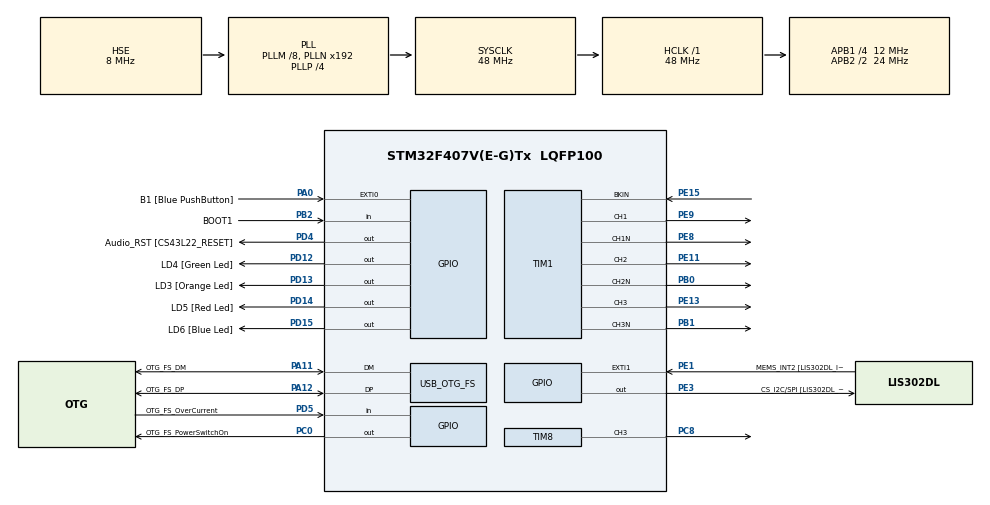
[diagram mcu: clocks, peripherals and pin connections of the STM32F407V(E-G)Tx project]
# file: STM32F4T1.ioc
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FREERTOS.Tasks01=defaultTask,0,128,StartDefaultTask,Default,NULL,Dynamic,NULL,NULL;TNBlinky,-3,128,ThreadBlinky,As external,NULL,Dynamic,NULL,NULL
Mcu.Family=STM32F4
Mcu.Name=STM32F407V(E-G)Tx
Mcu.Package=LQFP100
NVIC.OTG_FS_IRQn=true\:5\:0\:false\:false\:true\:true
NVIC.PriorityGroup=NVIC_PRIORITYGROUP_4
NVIC.TIM6_DAC_IRQn=true\:0\:0\:false\:false\:true\:false
NVIC.TimeBase=TIM6_DAC_IRQn
NVIC.TimeBaseIP=TIM6
PA0-WKUP.GPIO_Label=B1 [Blue PushButton]
PA0-WKUP.Signal=GPXTI0
PA10.GPIO_Label=OTG_FS_ID
PA10.GPIO_Mode=GPIO_MODE_AF_PP
PA10.GPIO_PuPd=GPIO_NOPULL
PA10.GPIO_Speed=GPIO_SPEED_FREQ_LOW
PA10.Signal=USB_OTG_FS_ID
PA11.GPIO_Label=OTG_FS_DM
PA11.GPIO_Mode=GPIO_MODE_AF_PP
PA11.GPIO_PuPd=GPIO_NOPULL
PA11.GPIO_Speed=GPIO_SPEED_FREQ_LOW
PA11.Mode=Device_Only
PA11.Signal=USB_OTG_FS_DM
PA12.GPIO_Label=OTG_FS_DP
PA12.GPIO_Mode=GPIO_MODE_AF_PP
PA12.GPIO_PuPd=GPIO_NOPULL
PA12.GPIO_Speed=GPIO_SPEED_FREQ_LOW
PA12.Mode=Device_Only
PA12.Signal=USB_OTG_FS_DP
PA13.GPIO_Label=SWDIO
PA13.Signal=SYS_JTMS-SWDIO
PA14.GPIO_Label=SWCLK
PA14.Signal=SYS_JTCK-SWCLK
PA4.GPIO_Label=I2S3_WS [CS43L22_LRCK]
PA4.GPIO_Mode=GPIO_MODE_AF_PP
PA4.GPIO_PuPd=GPIO_NOPULL
PA4.GPIO_Speed=GPIO_SPEED_FREQ_LOW
PA4.Signal=I2S3_WS
PA5.GPIO_Label=SPI1_SCK [LIS302DL_SCL/SPC]
PA5.GPIO_Mode=GPIO_MODE_AF_PP
PA5.GPIO_PuPd=GPIO_NOPULL
PA5.GPIO_Speed=GPIO_SPEED_FREQ_LOW
PA5.Signal=SPI1_SCK
PA6.GPIO_Label=SPI1_MISO [LIS302DL_SDO]
PA6.GPIO_Mode=GPIO_MODE_AF_PP
PA6.GPIO_PuPd=GPIO_NOPULL
PA6.GPIO_Speed=GPIO_SPEED_FREQ_LOW
PA6.Signal=SPI1_MISO
PA7.GPIO_Label=SPI1_MOSI [LIS302DL_SDA/SDI/SDO]
PA7.GPIO_Mode=GPIO_MODE_AF_PP
PA7.GPIO_PuPd=GPIO_NOPULL
PA7.GPIO_Speed=GPIO_SPEED_FREQ_LOW
PA7.Signal=SPI1_MOSI
PA9.GPIO_Label=VBUS_FS
PA9.GPIO_Mode=GPIO_MODE_INPUT
PA9.GPIO_PuPd=GPIO_NOPULL
PA9.Signal=USB_OTG_FS_VBUS
PB0.Mode=PWM Generation2 CH2 CH2N
PB0.Signal=TIM1_CH2N
PB1.Mode=PWM Generation3 CH3 CH3N
PB1.Signal=TIM1_CH3N
PB10.GPIO_Label=CLK_IN [MP45DT02_CLK]
PB10.GPIO_Mode=GPIO_MODE_AF_PP
PB10.GPIO_PuPd=GPIO_NOPULL
PB10.GPIO_Speed=GPIO_SPEED_FREQ_LOW
PB10.Signal=I2S2_CK
PB2.GPIO_Label=BOOT1
PB2.GPIO_Mode=GPIO_MODE_INPUT
PB2.GPIO_PuPd=GPIO_NOPULL
PB2.Signal=GPIO_Input
PB3.GPIO_Label=SWO
PB3.Signal=SYS_JTDO-SWO
PB6.GPIO_Label=Audio_SCL [CS43L22_SCL]
PB6.GPIO_Mode=GPIO_MODE_AF_OD
PB6.GPIO_PuPd=GPIO_NOPULL
PB6.GPIO_Speed=GPIO_SPEED_FREQ_LOW
PB6.Signal=I2C1_SCL
PB9.GPIO_Label=Audio_SDA [CS43L22_SDA]
PB9.GPIO_Mode=GPIO_MODE_AF_OD
PB9.GPIO_PuPd=GPIO_NOPULL
PB9.GPIO_Speed=GPIO_SPEED_FREQ_LOW
PB9.Signal=I2C1_SDA
PC0.GPIO_Label=OTG_FS_PowerSwitchOn
PC0.GPIO_PuPd=GPIO_NOPULL
PC0.GPIO_Speed=GPIO_SPEED_FREQ_LOW
PC0.PinState=GPIO_PIN_SET
PC0.Signal=GPIO_Output
PC10.GPIO_Label=I2S3_SCK [CS43L22_SCLK]
PC10.GPIO_Mode=GPIO_MODE_AF_PP
PC10.GPIO_PuPd=GPIO_NOPULL
PC10.GPIO_Speed=GPIO_SPEED_FREQ_LOW
PC10.Signal=I2S3_CK
PC12.GPIO_Label=I2S3_SD [CS43L22_SDIN]
PC12.GPIO_Mode=GPIO_MODE_AF_PP
PC12.GPIO_PuPd=GPIO_NOPULL
PC12.GPIO_Speed=GPIO_SPEED_FREQ_LOW
PC12.Signal=I2S3_SD
PC14-OSC32_IN.GPIO_Label=PC14-OSC32_IN
PC14-OSC32_IN.Mode=LSE-External-Oscillator
PC14-OSC32_IN.Signal=RCC_OSC32_IN
PC15-OSC32_OUT.GPIO_Label=PC15-OSC32_OUT
PC15-OSC32_OUT.Mode=LSE-External-Oscillator
PC15-OSC32_OUT.Signal=RCC_OSC32_OUT
PC3.GPIO_Label=PDM_OUT [MP45DT02_DOUT]
PC3.GPIO_Mode=GPIO_MODE_AF_PP
PC3.GPIO_PuPd=GPIO_NOPULL
PC3.GPIO_Speed=GPIO_SPEED_FREQ_LOW
PC3.Signal=I2S2_SD
PC7.GPIO_Label=I2S3_MCK [CS43L22_MCLK]
PC7.GPIO_Mode=GPIO_MODE_AF_PP
PC7.GPIO_PuPd=GPIO_NOPULL
PC7.GPIO_Speed=GPIO_SPEED_FREQ_LOW
PC7.Signal=I2S3_MCK
PC8.Signal=S_TIM8_CH3
PD12.GPIO_Label=LD4 [Green Led]
PD12.GPIO_PuPd=GPIO_NOPULL
PD12.GPIO_Speed=GPIO_SPEED_FREQ_LOW
PD12.Signal=GPIO_Output
PD13.GPIO_Label=LD3 [Orange Led]
PD13.GPIO_PuPd=GPIO_NOPULL
PD13.GPIO_Speed=GPIO_SPEED_FREQ_LOW
PD13.Signal=GPIO_Output
PD14.GPIO_Label=LD5 [Red Led]
PD14.GPIO_PuPd=GPIO_NOPULL
PD14.GPIO_Speed=GPIO_SPEED_FREQ_LOW
PD14.Signal=GPIO_Output
PD15.GPIO_Label=LD6 [Blue Led]
PD15.GPIO_PuPd=GPIO_NOPULL
PD15.GPIO_Speed=GPIO_SPEED_FREQ_LOW
PD15.Signal=GPIO_Output
PD4.GPIO_Label=Audio_RST [CS43L22_RESET]
PD4.GPIO_PuPd=GPIO_NOPULL
PD4.GPIO_Speed=GPIO_SPEED_FREQ_LOW
PD4.Signal=GPIO_Output
PD5.GPIO_Label=OTG_FS_OverCurrent
PD5.GPIO_Mode=GPIO_MODE_INPUT
PD5.GPIO_PuPd=GPIO_NOPULL
PD5.Signal=GPIO_Input
PE1.GPIO_Label=MEMS_INT2 [LIS302DL_INT2]
PE1.GPIO_ModeDefaultEXTI=GPIO_MODE_EVT_RISING
PE1.GPIO_PuPd=GPIO_NOPULL
PE1.Signal=GPXTI1
PE11.Signal=S_TIM1_CH2
PE13.Signal=S_TIM1_CH3
PE15.Mode=Activate-Break-Input
PE15.Signal=TIM1_BKIN
PE3.GPIO_Label=CS_I2C/SPI [LIS302DL_CS_I2C/SPI]
PE3.GPIO_PuPd=GPIO_NOPULL
PE3.GPIO_Speed=GPIO_SPEED_FREQ_LOW
PE3.Signal=GPIO_Output
PE8.Mode=PWM Generation1 CH1 CH1N
PE8.Signal=TIM1_CH1N
PE9.Signal=S_TIM1_CH1
PH0-OSC_IN.GPIO_Label=PH0-OSC_IN
PH0-OSC_IN.Mode=HSE-External-Oscillator
PH0-OSC_IN.Signal=RCC_OSC_IN
PH1-OSC_OUT.GPIO_Label=PH1-OSC_OUT
PH1-OSC_OUT.Mode=HSE-External-Oscillator
PH1-OSC_OUT.Signal=RCC_OSC_OUT
ProjectManager.HeapSize=0x200
ProjectManager.StackSize=0x400
ProjectManager.TargetToolchain=SW4STM32
RCC.48MHZClocksFreq_Value=48000000
RCC.AHBFreq_Value=48000000
RCC.APB1CLKDivider=RCC_HCLK_DIV4
RCC.APB1Freq_Value=12000000
RCC.APB1TimFreq_Value=24000000
RCC.APB2CLKDivider=RCC_HCLK_DIV2
RCC.APB2Freq_Value=24000000
RCC.APB2TimFreq_Value=48000000
RCC.CortexFreq_Value=48000000
RCC.HCLKFreq_Value=48000000
RCC.HSE_VALUE=8000000
RCC.HSI_VALUE=16000000
RCC.PLLM=8
RCC.PLLP=RCC_PLLP_DIV4
RCC.SYSCLKFreq_VALUE=48000000
RCC.SYSCLKSource=RCC_SYSCLKSOURCE_PLLCLK
RCC.VCOOutputFreq_Value=192000000
SH.S_TIM1_CH1.0=TIM1_CH1,PWM Generation1 CH1 CH1N
SH.S_TIM1_CH2.0=TIM1_CH2,PWM Generation2 CH2 CH2N
SH.S_TIM1_CH3.0=TIM1_CH3,PWM Generation3 CH3 CH3N
SH.S_TIM8_CH3.0=TIM8_CH3,PWM Generation3 CH3
TIM1.Channel-PWM\ Generation1\ CH1\ CH1N=TIM_CHANNEL_1
TIM1.Channel-PWM\ Generation2\ CH2\ CH2N=TIM_CHANNEL_2
TIM1.Channel-PWM\ Generation3\ CH3\ CH3N=TIM_CHANNEL_3
TIM8.Channel-PWM\ Generation3\ CH3=TIM_CHANNEL_3
USB_DEVICE.CLASS_NAME_FS=CDC
USB_DEVICE.VirtualModeFS=Cdc_FS
USB_OTG_FS.VirtualMode=Device_Only
VP_FREERTOS_VS_ENABLE.Mode=Enabled
VP_SYS_VS_tim6.Mode=TIM6
VP_TIM1_VS_ClockSourceINT.Mode=Internal
VP_USB_DEVICE_VS_USB_DEVICE_CDC_FS.Mode=CDC_FS
board=STM32F4DISCOVERY

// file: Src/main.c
/**
  ******************************************************************************
  * File Name          : main.c
  * Description        : Main program body
  ******************************************************************************
  *
  * Copyright (c) 2017 STMicroelectronics International N.V.
  * All rights reserved.
  *
  * Redistribution and use in source and binary forms, with or without
  * modification, are permitted, provided that the following conditions are met:
  *
  * 1. Redistribution of source code must retain the above copyright notice,
  *    this list of conditions and the following disclaimer.
  * 2. Redistributions in binary form must reproduce the above copyright notice,
  *    this list of conditions and the following disclaimer in the documentation
  *    and/or other materials provided with the distribution.
  * 3. Neither the name of STMicroelectronics nor the names of other
  *    contributors to this software may be used to endorse or promote products
  *    derived from this software without specific written permission.
  * 4. This software, including modifications and/or derivative works of this
  *    software, must execute solely and exclusively on microcontroller or
  *    microprocessor devices manufactured by or for STMicroelectronics.
  * 5. Redistribution and use of this software other than as permitted under
  *    this license is void and will automatically terminate your rights under
  *    this license.
  *
  * THIS SOFTWARE IS PROVIDED BY STMICROELECTRONICS AND CONTRIBUTORS "AS IS"
  * AND ANY EXPRESS, IMPLIED OR STATUTORY WARRANTIES, INCLUDING, BUT NOT
  * LIMITED TO, THE IMPLIED WARRANTIES OF MERCHANTABILITY, FITNESS FOR A
  * PARTICULAR PURPOSE AND NON-INFRINGEMENT OF THIRD PARTY INTELLECTUAL PROPERTY
  * RIGHTS ARE DISCLAIMED TO THE FULLEST EXTENT PERMITTED BY LAW. IN NO EVENT
  * SHALL STMICROELECTRONICS OR CONTRIBUTORS BE LIABLE FOR ANY DIRECT, INDIRECT,
  * INCIDENTAL, SPECIAL, EXEMPLARY, OR CONSEQUENTIAL DAMAGES (INCLUDING, BUT NOT
  * LIMITED TO, PROCUREMENT OF SUBSTITUTE GOODS OR SERVICES; LOSS OF USE, DATA,
  * OR PROFITS; OR BUSINESS INTERRUPTION) HOWEVER CAUSED AND ON ANY THEORY OF
  * LIABILITY, WHETHER IN CONTRACT, STRICT LIABILITY, OR TORT (INCLUDING
  * NEGLIGENCE OR OTHERWISE) ARISING IN ANY WAY OUT OF THE USE OF THIS SOFTWARE,
  * EVEN IF ADVISED OF THE POSSIBILITY OF SUCH DAMAGE.
  *
  ******************************************************************************
  */
#include "main.h"
#include "stm32f4xx_hal.h"
#include "cmsis_os.h"
#include "tim.h"
#include "usb_device.h"
#include "gpio.h"

/* USER CODE BEGIN PV */
/* Private variables ---------------------------------------------------------*/

/* USER CODE END PV */

void SystemClock_Config(void);
void Error_Handler(void);
void MX_FREERTOS_Init(void);

/* USER CODE BEGIN PFP */
/* Private function prototypes -----------------------------------------------*/

/* USER CODE END PFP */

int main(void)
{

  /* MCU Configuration----------------------------------------------------------*/

  /* Reset of all peripherals, Initializes the Flash interface and the Systick. */
  HAL_Init();

  /* Configure the system clock */
  SystemClock_Config();

  /* Initialize all configured peripherals */
  MX_GPIO_Init();
  MX_TIM1_Init();
  MX_TIM8_Init();

  /* Call init function for freertos objects (in freertos.c) */
  MX_FREERTOS_Init();

  /* Start scheduler */
  osKernelStart();

  /* We should never get here as control is now taken by the scheduler */

  /* Infinite loop */
  while (1)
  {

  }

}

/** System Clock Configuration
*/
void SystemClock_Config(void)
{

  RCC_OscInitTypeDef RCC_OscInitStruct;
  RCC_ClkInitTypeDef RCC_ClkInitStruct;

    /**Configure the main internal regulator output voltage
    */
  __HAL_RCC_PWR_CLK_ENABLE();

  __HAL_PWR_VOLTAGESCALING_CONFIG(PWR_REGULATOR_VOLTAGE_SCALE1);

    /**Initializes the CPU, AHB and APB busses clocks
    */
  RCC_OscInitStruct.OscillatorType = RCC_OSCILLATORTYPE_HSE;
  RCC_OscInitStruct.HSEState = RCC_HSE_ON;
  RCC_OscInitStruct.PLL.PLLState = RCC_PLL_ON;
  RCC_OscInitStruct.PLL.PLLSource = RCC_PLLSOURCE_HSE;
  RCC_OscInitStruct.PLL.PLLM = 8;
  RCC_OscInitStruct.PLL.PLLN = 192;
  RCC_OscInitStruct.PLL.PLLP = RCC_PLLP_DIV4;
  RCC_OscInitStruct.PLL.PLLQ = 4;
  if (HAL_RCC_OscConfig(&RCC_OscInitStruct) != HAL_OK)
  {
    Error_Handler();
  }

    /**Initializes the CPU, AHB and APB busses clocks
    */
  RCC_ClkInitStruct.ClockType = RCC_CLOCKTYPE_HCLK|RCC_CLOCKTYPE_SYSCLK
                              |RCC_CLOCKTYPE_PCLK1|RCC_CLOCKTYPE_PCLK2;
  RCC_ClkInitStruct.SYSCLKSource = RCC_SYSCLKSOURCE_PLLCLK;
  RCC_ClkInitStruct.AHBCLKDivider = RCC_SYSCLK_DIV1;
  RCC_ClkInitStruct.APB1CLKDivider = RCC_HCLK_DIV4;
  RCC_ClkInitStruct.APB2CLKDivider = RCC_HCLK_DIV2;

  if (HAL_RCC_ClockConfig(&RCC_ClkInitStruct, FLASH_LATENCY_1) != HAL_OK)
  {
    Error_Handler();
  }

    /**Configure the Systick interrupt time
    */
  HAL_SYSTICK_Config(HAL_RCC_GetHCLKFreq()/1000);

    /**Configure the Systick
    */
  HAL_SYSTICK_CLKSourceConfig(SYSTICK_CLKSOURCE_HCLK);

  /* SysTick_IRQn interrupt configuration */
  HAL_NVIC_SetPriority(SysTick_IRQn, 15, 0);
}

void HAL_TIM_PeriodElapsedCallback(TIM_HandleTypeDef *htim)
{
  if (htim->Instance == TIM6) {
    HAL_IncTick();
  }
}

void Error_Handler(void)
{
  while(1)
  {
  }
}

/************************ (C) COPYRIGHT STMicroelectronics *****END OF FILE****/

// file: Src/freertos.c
/**
  ******************************************************************************
  * File Name          : freertos.c
  * Description        : Code for freertos applications
  ******************************************************************************
  *
  * Copyright (c) 2017 STMicroelectronics International N.V.
  * All rights reserved.
  *
  * Redistribution and use in source and binary forms, with or without
  * modification, are permitted, provided that the following conditions are met:
  *
  * 1. Redistribution of source code must retain the above copyright notice,
  *    this list of conditions and the following disclaimer.
  * 2. Redistributions in binary form must reproduce the above copyright notice,
  *    this list of conditions and the following disclaimer in the documentation
  *    and/or other materials provided with the distribution.
  * 3. Neither the name of STMicroelectronics nor the names of other
  *    contributors to this software may be used to endorse or promote products
  *    derived from this software without specific written permission.
  * 4. This software, including modifications and/or derivative works of this
  *    software, must execute solely and exclusively on microcontroller or
  *    microprocessor devices manufactured by or for STMicroelectronics.
  * 5. Redistribution and use of this software other than as permitted under
  *    this license is void and will automatically terminate your rights under
  *    this license.
  *
  * THIS SOFTWARE IS PROVIDED BY STMICROELECTRONICS AND CONTRIBUTORS "AS IS"
  * AND ANY EXPRESS, IMPLIED OR STATUTORY WARRANTIES, INCLUDING, BUT NOT
  * LIMITED TO, THE IMPLIED WARRANTIES OF MERCHANTABILITY, FITNESS FOR A
  * PARTICULAR PURPOSE AND NON-INFRINGEMENT OF THIRD PARTY INTELLECTUAL PROPERTY
  * RIGHTS ARE DISCLAIMED TO THE FULLEST EXTENT PERMITTED BY LAW. IN NO EVENT
  * SHALL STMICROELECTRONICS OR CONTRIBUTORS BE LIABLE FOR ANY DIRECT, INDIRECT,
  * INCIDENTAL, SPECIAL, EXEMPLARY, OR CONSEQUENTIAL DAMAGES (INCLUDING, BUT NOT
  * LIMITED TO, PROCUREMENT OF SUBSTITUTE GOODS OR SERVICES; LOSS OF USE, DATA,
  * OR PROFITS; OR BUSINESS INTERRUPTION) HOWEVER CAUSED AND ON ANY THEORY OF
  * LIABILITY, WHETHER IN CONTRACT, STRICT LIABILITY, OR TORT (INCLUDING
  * NEGLIGENCE OR OTHERWISE) ARISING IN ANY WAY OUT OF THE USE OF THIS SOFTWARE,
  * EVEN IF ADVISED OF THE POSSIBILITY OF SUCH DAMAGE.
  *
  ******************************************************************************
  */

#include "FreeRTOS.h"
#include "task.h"
#include "cmsis_os.h"

/* USER CODE BEGIN Includes */
#include "intersect/DefaultTask.h"
/* USER CODE END Includes */

osThreadId defaultTaskHandle;

void StartDefaultTask(void const * argument);

extern void MX_USB_DEVICE_Init(void);
void MX_FREERTOS_Init(void); /* (MISRA C 2004 rule 8.1) */

/* Hook prototypes */

/* Init FreeRTOS */

void MX_FREERTOS_Init(void) {

  /* Create the thread(s) */
  /* definition and creation of defaultTask */
  osThreadDef(defaultTask, StartDefaultTask, osPriorityNormal, 0, 128);
  defaultTaskHandle = osThreadCreate(osThread(defaultTask), NULL);

}

/* StartDefaultTask function */
void StartDefaultTask(void const * argument)
{
  /* init code for USB_DEVICE */
  MX_USB_DEVICE_Init();

  /* USER CODE BEGIN StartDefaultTask */
  DefaultTaskEntry();
  /* Infinite loop */
  for(;;)
  {
    osDelay(1);
  }
  /* USER CODE END StartDefaultTask */
}

/************************ (C) COPYRIGHT STMicroelectronics *****END OF FILE****/
